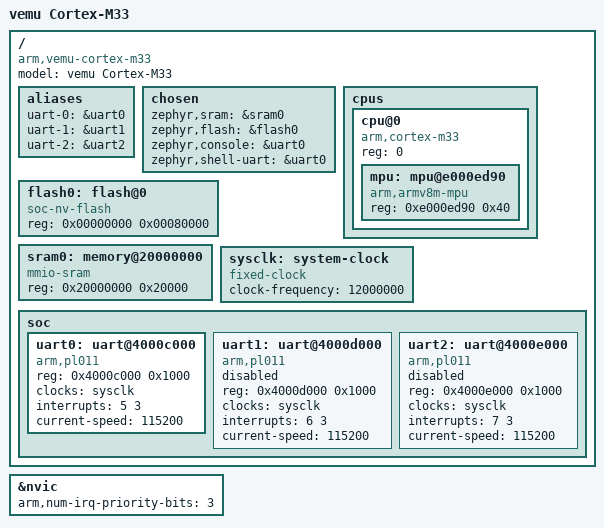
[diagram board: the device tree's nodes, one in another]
/* Copyright (c) 2026 Martin Schröder <info@swedishembedded.com> */
/* SPDX-License-Identifier: Apache-2.0 */

/dts-v1/;

#include <arm/armv8-m.dtsi>
#include <zephyr/dt-bindings/i2c/i2c.h>

/ {
	model = "vemu Cortex-M33";
	compatible = "arm,vemu-cortex-m33";
	#address-cells = <1>;
	#size-cells = <1>;

	aliases {
		uart-0 = &uart0;
		uart-1 = &uart1;
		uart-2 = &uart2;
	};

	chosen {
		zephyr,sram = &sram0;
		zephyr,flash = &flash0;
		zephyr,console = &uart0;
		zephyr,shell-uart = &uart0;
	};

	cpus {
		#address-cells = <1>;
		#size-cells = <0>;

		cpu@0 {
			device_type = "cpu";
			compatible = "arm,cortex-m33";
			reg = <0>;
			#address-cells = <1>;
			#size-cells = <1>;

			mpu: mpu@e000ed90 {
				compatible = "arm,armv8m-mpu";
				reg = <0xe000ed90 0x40>;
			};
		};
	};

	flash0: flash@0 {
		compatible = "soc-nv-flash";
		reg = <0x00000000 0x00080000>;
	};

	sram0: memory@20000000 {
		compatible = "mmio-sram";
		reg = <0x20000000 0x20000>;
	};

	sysclk: system-clock {
		compatible = "fixed-clock";
		clock-frequency = <12000000>;
		#clock-cells = <0>;
	};

	soc {
		uart0: uart@4000c000 {
			compatible = "arm,pl011";
			reg = <0x4000c000 0x1000>;
			clocks = <&sysclk>;
			interrupts = <5 3>;
			status = "okay";
			current-speed = <115200>;
		};

		uart1: uart@4000d000 {
			compatible = "arm,pl011";
			reg = <0x4000d000 0x1000>;
			clocks = <&sysclk>;
			interrupts = <6 3>;
			status = "disabled";
			current-speed = <115200>;
		};

		uart2: uart@4000e000 {
			compatible = "arm,pl011";
			reg = <0x4000e000 0x1000>;
			clocks = <&sysclk>;
			interrupts = <7 3>;
			status = "disabled";
			current-speed = <115200>;
		};
	};
};

&nvic {
	arm,num-irq-priority-bits = <3>;
};
